# netx90_app register map
File version: 1.0
CPU: CM4 r0p1, little endian, MPU, FPU, 4 interrupt priority bits, 78 interrupts
Registers are 32-bit, read-write, reset 0x0 unless marked. A register's access mark holds for its fields unless they carry their own. Offsets are from the block's base; [hi:lo] are bit positions; 'fields as' and 'values as' point back to an identical list.

## systime_app
Base 0xFF8016C0
0x00 systime_s — Upper SYSTIME register: To allow consistent values of systime_s and systime_ns, lower bits of systime is latched to systime_ns, when systime_s is read. This register should be dedicated to accesses via DPM. ARM software should access systime via arm_timer_systime_s. xPIC software should access systime via xpic_timer_systime_s.
  [31:0] systime_s — systime high value is incremented, if systime_ns reaches systime_border Sample systime_ns at read access to systime_s.
0x04 systime_ns — Lower SYSTIME register: To allow consistent values of systime_s and systime_ns, lower bits of systime is latched to systime_ns, when systime_s is read. If no systime_s is read before (or at 2nd read access of systime_ns), the actual value of systime_ns is read. This register should be dedicated to accesses via DPM. ARM software should access systime via arm_timer_systime_ns. xPIC software should access systime via xpic_timer_systime_ns.
  [31:0] systime_ns — Systime low: Sample systime_ns at read access to systime_s. Without sample read systime_s, read the actual value of systime_ns.
0x08 systime_border reset 0x3B9AC9FF
  [31:0] systime_border — Systime border for lower systime: systime_ns counts from 0 to this value (inlcuded), i.e. systime_ns counts modulo (systime_border + 1) Attention: the border value Bit 3 to 1 must be b'1111 (hex f) for all netX systime - match functions
0x0C systime_count_value reset 0xA0000000 — SYSTIME count register
  [31:0] systime_count_value — Each clock cycle (systime_count_value >> 28) will be added to systime (rate multiplier for IEEE1588). Value 0x10000000 can be used for counting in 10ns (ethernet clock) steps.

## mcp_app
Base 0xFF8016E0
Same registers: mcp_xpic_app 0xFF9001A0
0x00 hs_irq_set_raw — read: hs_iq_reg value write: hs_iq_reg set bit(s)
  [31:0] hs_irq_set_bits — IRQs for Inter-CPU-Communication
0x04 hs_irq_reset_raw — read: hs_iq_reg value write: hs_iq_reg reset bit(s)
  [31:0] hs_irq_reset_bits — IRQs for Inter-CPU-Communication
0x08 hs_irq_set_mask — read: mask value
  [31:0] hs_irq_set_mask — IRQs for Inter-CPU-Communication
0x0C hs_irq_reset_mask — read: mask value
  [31:0] hs_irq_reset_mask — reset IRQs for Inter-CPU-Communication
0x10 hs_irq_masked — read: hs_iq_reg masked value
  [31:0] hs_irq_masked — mask IRQs for Inter-CPU-Communication

## trigger_irq_app
Base 0xFF801720
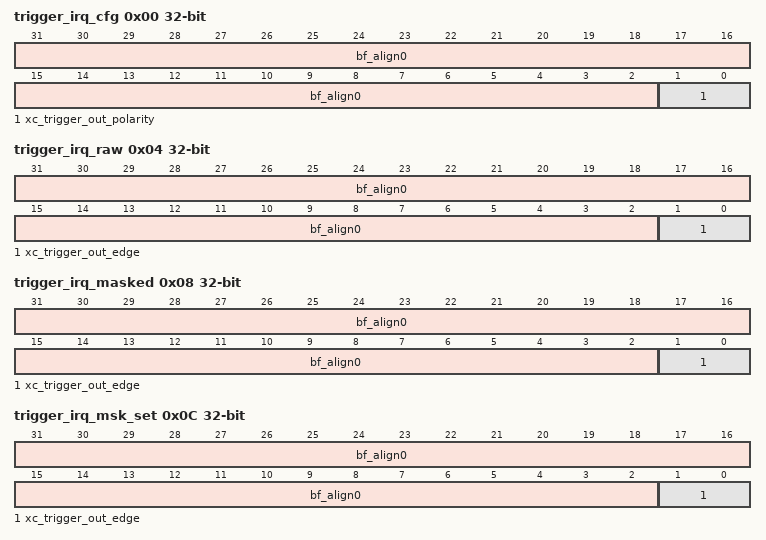
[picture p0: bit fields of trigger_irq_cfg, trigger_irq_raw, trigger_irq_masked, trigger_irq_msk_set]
0x00 trigger_irq_cfg (reset mask 0x3) — Trigger IRQ configuration register.
  [31:2] bf_align0 — bitField alignment value for aeabi compatibility
  [1:0] xc_trigger_out_polarity — Polarity of xc_trigger_out signals for edge detection. 0: Use pos-edge on xc_trigger_out signals to trigger an IRQ. 1: Use neg-edge on xc_trigger_out signals to trigger an IRQ. Note: Changing the polarity will trigger set an IRQ in the raw register (and when the mask is set also the IRQ signal to the CPU) due to the edge detection logic.
0x04 trigger_irq_raw (reset mask 0x3) — Trigger raw IRQ: Read access shows status of unmasked IRQs. IRQs are set automatically and reset by writing to this register: Write access with '1' resets the appropriate IRQ. Write access with '0' does not influence this bit.
  [31:2] bf_align0 — bitField alignment value for aeabi compatibility
  [1:0] xc_trigger_out_edge — Edge detected on xc_trigger_out.
0x08 trigger_irq_masked ro (reset mask 0x3) — Trigger masked IRQ: Shows status of masked IRQs.
  fields as trigger_irq_raw
0x0C trigger_irq_msk_set (reset mask 0x3) — Trigger IRQ mask set: The IRQ mask enables interrupt requests for corresponding interrupt sources. As its bits might be changed by different software tasks, the IRQ mask register is not writable directly, but by set and reset masks: Write access with '1' sets interrupt mask bit. Write access with '0' does not influence this bit. Read access shows actual interrupt mask. Attention: Before activating interrupt mask, delete old pending interrupts by writing the same value to bod_irq_raw.
  fields as trigger_irq_raw
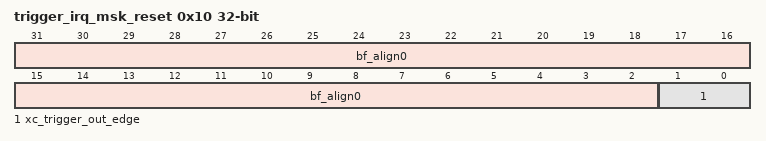
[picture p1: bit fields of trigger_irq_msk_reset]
0x10 trigger_irq_msk_reset (reset mask 0x3) — Trigger IRQ mask reset: This is the corresponding reset mask to disable interrupt requests for corresponding interrupt sources: Write access with '1' resets interrupt mask bit. Write access with '0' does not influence this bit. Read access shows actual interrupt mask.
  fields as trigger_irq_raw
